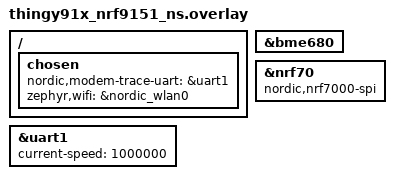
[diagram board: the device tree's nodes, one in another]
/*
 * Copyright (c) 2024 Nordic Semiconductor ASA
 *
 * SPDX-License-Identifier: LicenseRef-Nordic-5-Clause
 */

#include <thingy91x_wifi.dtsi>

&bme680 {
	status = "okay";
};

/ {
	chosen {
		nordic,modem-trace-uart = &uart1;
		zephyr,wifi = &nordic_wlan0;
	};
};

&uart1 {
	status = "okay";
	current-speed = <1000000>;
};

/* Switch to nrf7000 emulation so that scan-only mode is used. */
&nrf70 {
	compatible = "nordic,nrf7000-spi";
};


/* Flash partitions (littlefs_storage, MCUboot slots, etc.) */
/delete-node/ &b0_partition;
/delete-node/ &s0_partition;
/delete-node/ &s1_partition;
/delete-node/ &external_flash_partition;
#include "att_flash_partitions.dtsi"
#include "att_sram_partitions.dtsi"
